AUTOSAR XML (schema 4-2-2)
package /ComponentTypes
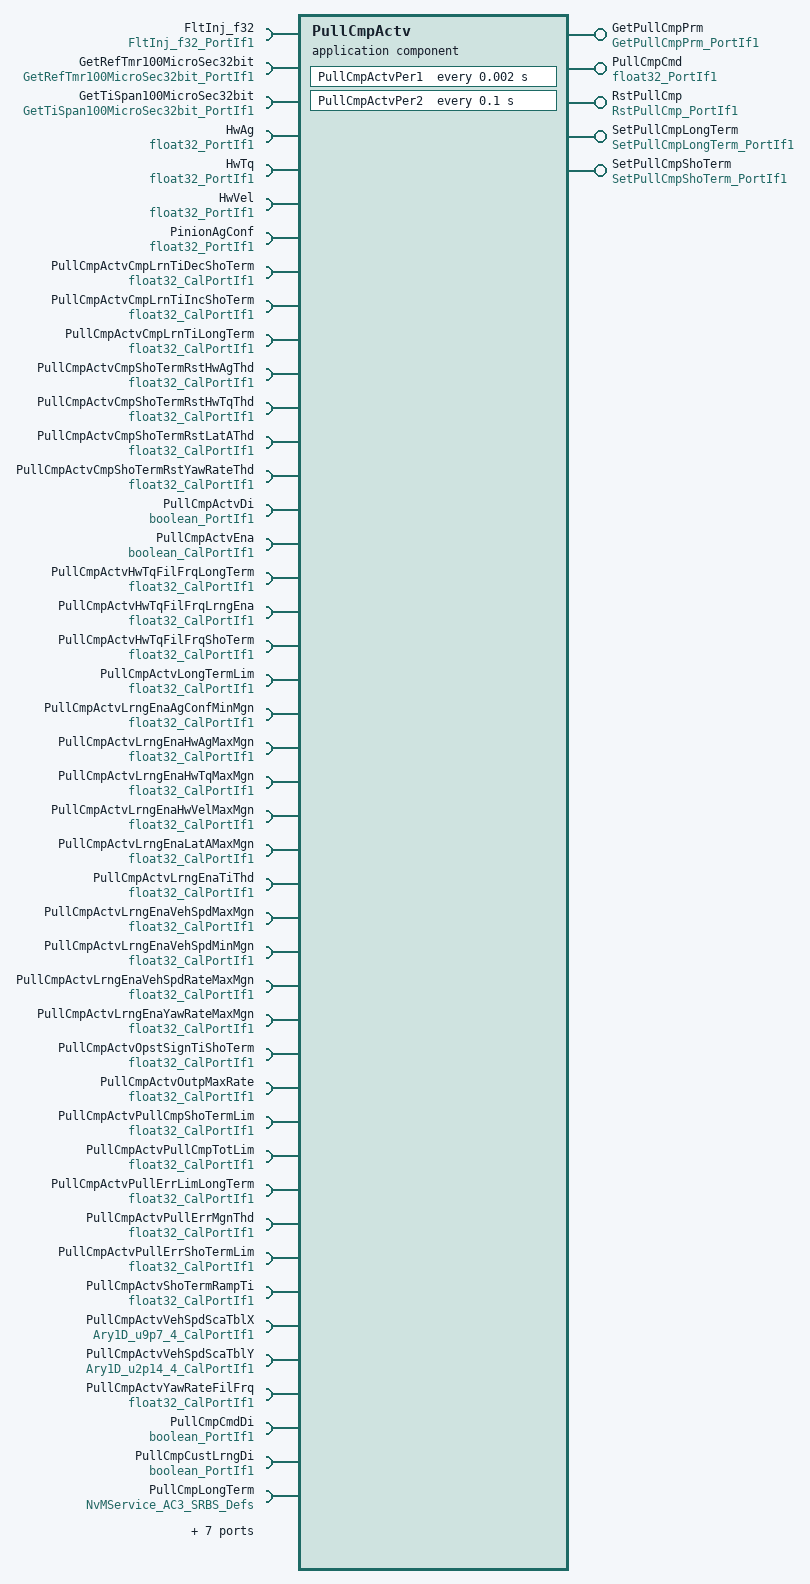
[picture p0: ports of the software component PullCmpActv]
  application sw component type PullCmpActv
    5 x provide port:
      GetPullCmpPrm: server-com-spec{operation=Oper, queue-length=1}, provided-interface=GetPullCmpPrm_PortIf1
      PullCmpCmd: nonqueued-sender-com-spec{data-element=Val, init-value=0}, provided-interface=float32_PortIf1
      RstPullCmp: server-com-spec{operation=Oper, queue-length=1}, provided-interface=RstPullCmp_PortIf1
      SetPullCmpLongTerm: server-com-spec{operation=Oper, queue-length=1}, provided-interface=SetPullCmpLongTerm_PortIf1
      SetPullCmpShoTerm: server-com-spec{operation=Oper, queue-length=1}, provided-interface=SetPullCmpShoTerm_PortIf1
    51 x require port:
      FltInj_f32: client-com-spec=Oper, required-interface=FltInj_f32_PortIf1
      GetRefTmr100MicroSec32bit: client-com-spec=Oper, required-interface=GetRefTmr100MicroSec32bit_PortIf1
      GetTiSpan100MicroSec32bit: client-com-spec=Oper, required-interface=GetTiSpan100MicroSec32bit_PortIf1
      HwAg: nonqueued-receiver-com-spec{data-element=Val, filter=data-filter-type=ALWAYS, init-value=0}, required-interface=float32_PortIf1
      HwTq: nonqueued-receiver-com-spec{data-element=Val, filter=data-filter-type=ALWAYS, init-value=0}, required-interface=float32_PortIf1
      HwVel: nonqueued-receiver-com-spec{data-element=Val, filter=data-filter-type=ALWAYS, init-value=0}, required-interface=float32_PortIf1
      PinionAgConf: nonqueued-receiver-com-spec{data-element=Val, filter=data-filter-type=ALWAYS, init-value=0}, required-interface=float32_PortIf1
      PullCmpActvCmpLrnTiDecShoTerm: parameter-require-com-spec{init-value=45, parameter=Val}, required-interface=float32_CalPortIf1
      PullCmpActvCmpLrnTiIncShoTerm: parameter-require-com-spec{init-value=45, parameter=Val}, required-interface=float32_CalPortIf1
      PullCmpActvCmpLrnTiLongTerm: parameter-require-com-spec{init-value=45, parameter=Val}, required-interface=float32_CalPortIf1
      PullCmpActvCmpShoTermRstHwAgThd: parameter-require-com-spec{init-value=45, parameter=Val}, required-interface=float32_CalPortIf1
      PullCmpActvCmpShoTermRstHwTqThd: parameter-require-com-spec{init-value=3, parameter=Val}, required-interface=float32_CalPortIf1
      PullCmpActvCmpShoTermRstLatAThd: parameter-require-com-spec{init-value=1, parameter=Val}, required-interface=float32_CalPortIf1
      PullCmpActvCmpShoTermRstYawRateThd: parameter-require-com-spec{init-value=1, parameter=Val}, required-interface=float32_CalPortIf1
      PullCmpActvDi: nonqueued-receiver-com-spec{data-element=Logl, filter=data-filter-type=ALWAYS, init-value=0}, required-interface=boolean_PortIf1
      PullCmpActvEna: parameter-require-com-spec{init-value=1, parameter=Logl}, required-interface=boolean_CalPortIf1
      PullCmpActvHwTqFilFrqLongTerm: parameter-require-com-spec{init-value=0.5, parameter=Val}, required-interface=float32_CalPortIf1
      PullCmpActvHwTqFilFrqLrngEna: parameter-require-com-spec{init-value=20, parameter=Val}, required-interface=float32_CalPortIf1
      PullCmpActvHwTqFilFrqShoTerm: parameter-require-com-spec{init-value=0.5, parameter=Val}, required-interface=float32_CalPortIf1
      PullCmpActvLongTermLim: parameter-require-com-spec{init-value=0.5, parameter=Val}, required-interface=float32_CalPortIf1
      PullCmpActvLrngEnaAgConfMinMgn: parameter-require-com-spec{init-value=1, parameter=Val}, required-interface=float32_CalPortIf1
      PullCmpActvLrngEnaHwAgMaxMgn: parameter-require-com-spec{init-value=45, parameter=Val}, required-interface=float32_CalPortIf1
      PullCmpActvLrngEnaHwTqMaxMgn: parameter-require-com-spec{init-value=2.8, parameter=Val}, required-interface=float32_CalPortIf1
      PullCmpActvLrngEnaHwVelMaxMgn: parameter-require-com-spec{init-value=10, parameter=Val}, required-interface=float32_CalPortIf1
      PullCmpActvLrngEnaLatAMaxMgn: parameter-require-com-spec{init-value=0.5, parameter=Val}, required-interface=float32_CalPortIf1
      PullCmpActvLrngEnaTiThd: parameter-require-com-spec{init-value=2, parameter=Val}, required-interface=float32_CalPortIf1
      PullCmpActvLrngEnaVehSpdMaxMgn: parameter-require-com-spec{init-value=160, parameter=Val}, required-interface=float32_CalPortIf1
      PullCmpActvLrngEnaVehSpdMinMgn: parameter-require-com-spec{init-value=60, parameter=Val}, required-interface=float32_CalPortIf1
      PullCmpActvLrngEnaVehSpdRateMaxMgn: parameter-require-com-spec{init-value=1, parameter=Val}, required-interface=float32_CalPortIf1
      PullCmpActvLrngEnaYawRateMaxMgn: parameter-require-com-spec{init-value=1, parameter=Val}, required-interface=float32_CalPortIf1
      PullCmpActvOpstSignTiShoTerm: parameter-require-com-spec{init-value=0.1, parameter=Val}, required-interface=float32_CalPortIf1
      PullCmpActvOutpMaxRate: parameter-require-com-spec{init-value=100, parameter=Val}, required-interface=float32_CalPortIf1
      PullCmpActvPullCmpShoTermLim: parameter-require-com-spec{init-value=1, parameter=Val}, required-interface=float32_CalPortIf1
      PullCmpActvPullCmpTotLim: parameter-require-com-spec{init-value=0, parameter=Val}, required-interface=float32_CalPortIf1
      PullCmpActvPullErrLimLongTerm: parameter-require-com-spec{init-value=3, parameter=Val}, required-interface=float32_CalPortIf1
      PullCmpActvPullErrMgnThd: parameter-require-com-spec{init-value=0.25, parameter=Val}, required-interface=float32_CalPortIf1
      PullCmpActvPullErrShoTermLim: parameter-require-com-spec{init-value=3, parameter=Val}, required-interface=float32_CalPortIf1
      PullCmpActvShoTermRampTi: parameter-require-com-spec{init-value=1, parameter=Val}, required-interface=float32_CalPortIf1
      PullCmpActvVehSpdScaTblX: parameter-require-com-spec{init-value=[0, 3840, 7680, 11520], parameter=Ary1D}, required-interface=Ary1D_u9p7_4_CalPortIf1
      PullCmpActvVehSpdScaTblY: parameter-require-com-spec{init-value=[0, 4096, 16384, 16384], parameter=Ary1D}, required-interface=Ary1D_u2p14_4_CalPortIf1
      PullCmpActvYawRateFilFrq: parameter-require-com-spec{init-value=3, parameter=Val}, required-interface=float32_CalPortIf1
      PullCmpCmdDi: nonqueued-receiver-com-spec{data-element=Logl, filter=data-filter-type=ALWAYS, init-value=0}, required-interface=boolean_PortIf1
      PullCmpCustLrngDi: nonqueued-receiver-com-spec{data-element=Logl, filter=data-filter-type=ALWAYS, init-value=0}, required-interface=boolean_PortIf1
      PullCmpLongTerm: required-com-specs=[EraseBlock, GetErrorStatus, InvalidateNvBlock, ReadBlock, RestoreBlockDefaults, SetRamBlockStatus, WriteBlock], required-interface=NvMService_AC3_SRBS_Defs
      PullCmpLrngDi: nonqueued-receiver-com-spec{data-element=Logl, filter=data-filter-type=ALWAYS, init-value=0}, required-interface=boolean_PortIf1
      SysGlbPrmSysTqRat: parameter-require-com-spec{init-value=20, parameter=Val}, required-interface=float32_CalPortIf1
      VehLatA: nonqueued-receiver-com-spec{data-element=Val, filter=data-filter-type=ALWAYS, init-value=0}, required-interface=float32_PortIf1
      VehSpd: nonqueued-receiver-com-spec{data-element=Val, filter=data-filter-type=ALWAYS, init-value=0}, required-interface=float32_PortIf1
      VehSpdVld: nonqueued-receiver-com-spec{data-element=Logl, filter=data-filter-type=ALWAYS, init-value=0}, required-interface=boolean_PortIf1
      VehYawRate: nonqueued-receiver-com-spec{data-element=Val, filter=data-filter-type=ALWAYS, init-value=0}, required-interface=float32_PortIf1
      VehYawRateVld: nonqueued-receiver-com-spec{data-element=Logl, filter=data-filter-type=ALWAYS, init-value=0}, required-interface=boolean_PortIf1
    behavior PullCmpActv_InternalBehavior
      ar-typed-per-instance-memorys:
        28 x data, all with sw-calibration-access=READ-ONLY:
          CmpLrnTiDecShoTerm: type=float32
          CmpLrnTiIncShoTerm: type=float32
          CmpLrnTiLongTerm: type=float32
          dPullCmpActvIntgtrGainShoTerm: type=float32
          dPullCmpActvPullErrLongTerm: type=float32
          dPullCmpActvPullErrShoTerm: type=float32
          dPullCmpActvShoTermRst: type=boolean
          HwTqLpFilLongTerm: type=FilLpRec1
          HwTqLpFilLrngEna: type=FilLpRec1
          HwTqLpFilShoTerm: type=FilLpRec1
          IntgtrGainDecShoTerm: type=float32
          IntgtrGainIncShoTerm: type=float32
          LrngEnad: type=boolean
          LrngEnaPrev: type=boolean
          OpstSignPrev: type=boolean
          PrevLrnTiLongTerm: type=float32
          PullCmpActvDi: type=boolean
          PullCmpCmdRateLimPrev: type=float32
          PullCmpCmdTot: type=float32
          PullCmpLongTerm: type=float32
          PullCmpLongTermRst: type=boolean
          PullCmpShoTerm: type=float32
          PullCmpShoTermRst: type=boolean
          RefTiEnaLrng: type=uint32
          RefTiOpstSign: type=uint32
          VehSpdPrev: type=float32
          VehSpdRate: type=float32
          VehYawRateLpFil: type=FilLpRec1
      operation invoked event OIT_GetPullCmpPrm_Oper_GetPullCmpPrm_Oper: start-on-event=GetPullCmpPrm_Oper, operation=GetPullCmpPrm.Oper
      init event PullCmpActv_InitEvent: start-on-event=PullCmpActvInit1
      timing event TMT_PullCmpActvPer1: start-on-event=PullCmpActvPer1, period=0.002
      timing event TMT_PullCmpActvPer2: start-on-event=PullCmpActvPer2, period=0.1
      operation invoked event OIT_RstPullCmp_Oper_RstPullCmp_Oper: start-on-event=RstPullCmp_Oper, operation=RstPullCmp.Oper
      operation invoked event OIT_SetPullCmpLongTerm_Oper_SetPullCmpLongTerm_Oper: start-on-event=SetPullCmpLongTerm_Oper, operation=SetPullCmpLongTerm.Oper
      operation invoked event OIT_SetPullCmpShoTerm_Oper_SetPullCmpShoTerm_Oper: start-on-event=SetPullCmpShoTerm_Oper, operation=SetPullCmpShoTerm.Oper
      explicit-inter-runnable-variables:
        data RampDwnStepSize: type=float32, init-value=0
      port-api-options:
        enable-take-address=false, error-handling=NO-TRANSFORMER-ERROR-HANDLING, indirect-api=false, port=FltInj_f32
        enable-take-address=false, error-handling=NO-TRANSFORMER-ERROR-HANDLING, indirect-api=false, port=PullCmpLongTerm
      7 x runnable:
        GetPullCmpPrm_Oper
        PullCmpActvInit1
          sync call SC_PullCmpLongTerm_GetErrorStatus: operation=PullCmpLongTerm.GetErrorStatus, timeout=0
          sync call SC_PullCmpLongTerm_SetRamBlockStatus: operation=PullCmpLongTerm.SetRamBlockStatus, timeout=0
          written-local-variables:
            access WRITE_RampDwnStepSize: accessed-variable=RampDwnStepSize
        PullCmpActvPer1
          data-receive-point-by-arguments:
            13 x access:
              REC_HwAg_Val: accessed-variable=HwAg.Val
              REC_HwTq_Val: accessed-variable=HwTq.Val
              REC_HwVel_Val: accessed-variable=HwVel.Val
              REC_PinionAgConf_Val: accessed-variable=PinionAgConf.Val
              REC_PullCmpActvDi_Logl: accessed-variable=PullCmpActvDi.Logl
              REC_PullCmpCmdDi_Logl: accessed-variable=PullCmpCmdDi.Logl
              REC_PullCmpCustLrngDi_Logl: accessed-variable=PullCmpCustLrngDi.Logl
              REC_PullCmpLrngDi_Logl: accessed-variable=PullCmpLrngDi.Logl
              REC_VehLatA_Val: accessed-variable=VehLatA.Val
              REC_VehSpd_Val: accessed-variable=VehSpd.Val
              REC_VehSpdVld_Logl: accessed-variable=VehSpdVld.Logl
              REC_VehYawRate_Val: accessed-variable=VehYawRate.Val
              REC_VehYawRateVld_Logl: accessed-variable=VehYawRateVld.Logl
          data-send-points:
            access SEND_PullCmpCmd_Val: accessed-variable=PullCmpCmd.Val
          read-local-variables:
            access READ_RampDwnStepSize: accessed-variable=RampDwnStepSize
          sync call SC_FltInj_f32_Oper: operation=FltInj_f32.Oper, timeout=0
          sync call SC_GetRefTmr100MicroSec32bit_PortIf1_Oper: operation=GetRefTmr100MicroSec32bit.Oper, timeout=0
          sync call SC_GetTiSpan100MicroSec32bit_PortIf1_Oper: operation=GetTiSpan100MicroSec32bit.Oper, timeout=0
        PullCmpActvPer2
          data-receive-point-by-arguments:
            access REC_HwTq_Val: accessed-variable=HwTq.Val
            access REC_VehSpd_Val: accessed-variable=VehSpd.Val
        RstPullCmp_Oper
        SetPullCmpLongTerm_Oper
          sync call SC_PullCmpLongTerm_SetRamBlockStatus: operation=PullCmpLongTerm.SetRamBlockStatus, timeout=0
        SetPullCmpShoTerm_Oper
      swc service dependency NvmPullCmpLongTerm: assigned-ports=role-based-port-assignment={port-prototype=PullCmpLongTerm, role=NvMService_AC3_SRBS_Defs}
        assigned-datas:
          role=ramBlock, used-data-element=PullCmpLongTerm
          role=defaultValue, used-parameter-element=PullCmpLongTermDft
        service-needs:
          nv block needs NvmPullCmpLongTerm: n-data-sets=0, ram-block-status-control=API, readonly=false, reliability=ERROR-DETECTION, resistant-to-changed-sw=true, restore-at-start=true, store-at-shutdown=true, write-only-once=false, writing-frequency=0, writing-priority=LOW
      shared-parameters:
        parameter data prototype PullCmpLongTermDft: sw-calibration-access=READ-WRITE, type=float32, init-value=0
  swc implementation PullCmpActv_Implementation: behavior=PullCmpActv_InternalBehavior
    code-descriptors:
      code Default: artifact-descriptors=autosar-engineering-object={short-label=Default, category=SWSRC}
